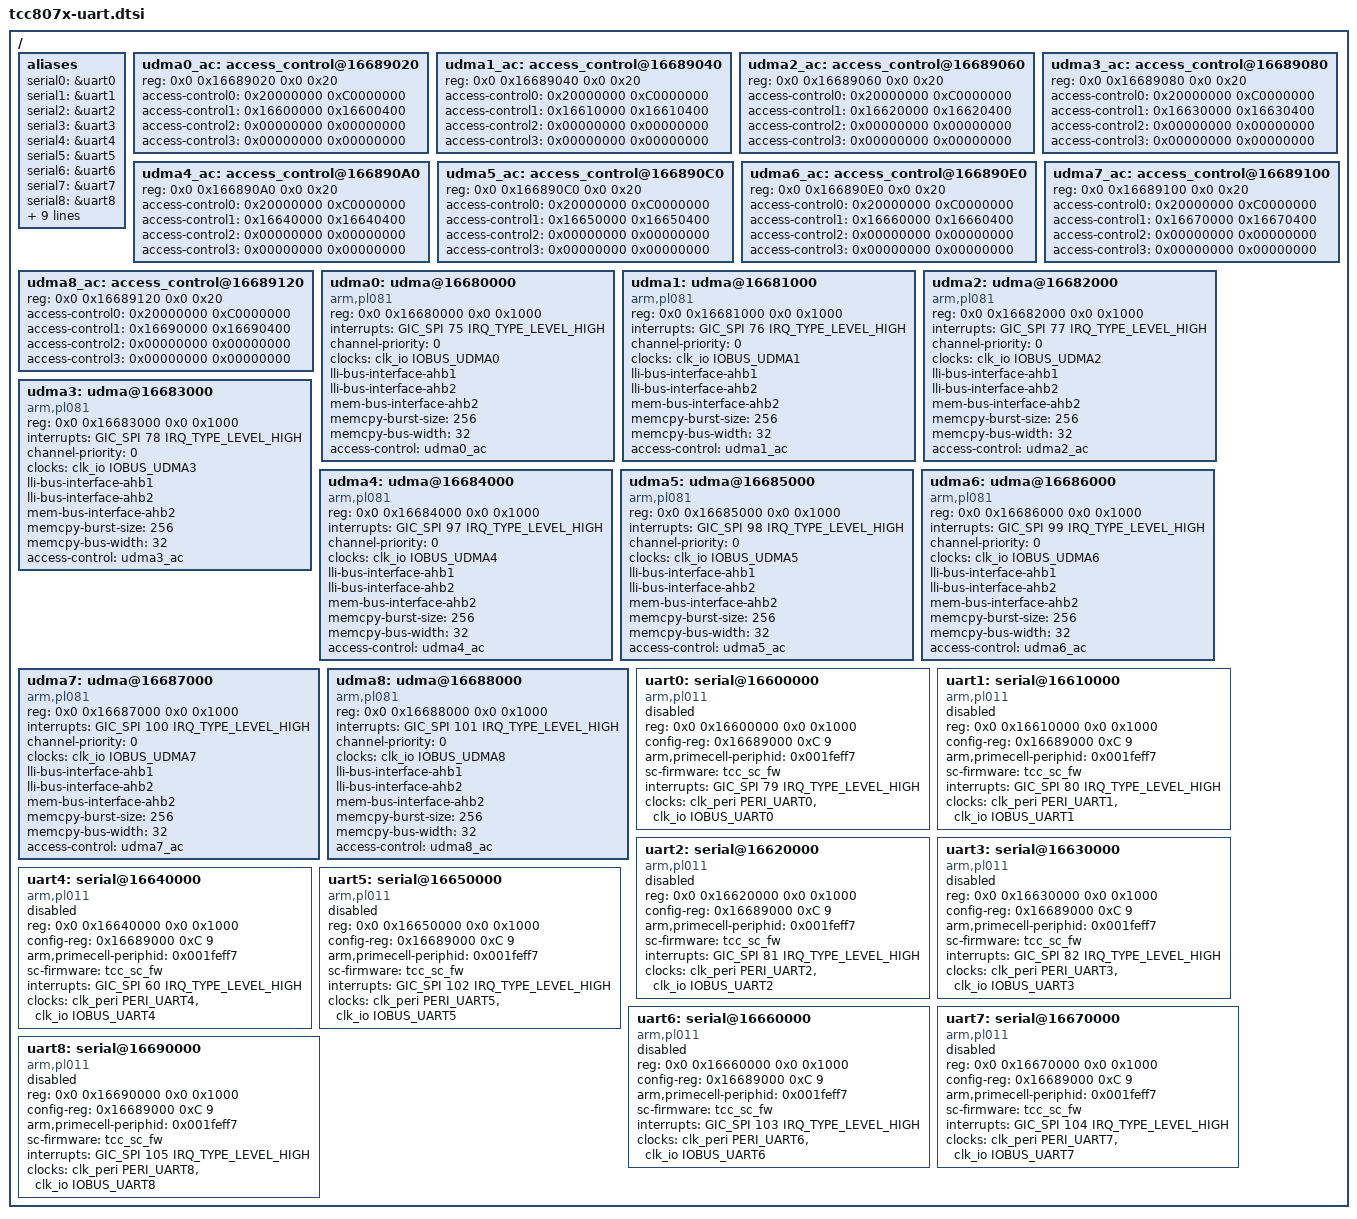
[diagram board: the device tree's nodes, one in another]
// SPDX-License-Identifier: (GPL-2.0-or-later OR MIT)
/*
 * Copyright (C) 2023 Telechips Inc.
 */

#include <dt-bindings/clock/telechips,tcc807x-clks.h>
#include <dt-bindings/interrupt-controller/arm-gic.h>

/ {
	aliases: aliases {
		serial0 = &uart0;
		serial1 = &uart1;
		serial2 = &uart2;
		serial3 = &uart3;
		serial4 = &uart4;
		serial5 = &uart5;
		serial6 = &uart6;
		serial7 = &uart7;
		serial8 = &uart8;
		udma0 = &udma0;
		udma1 = &udma1;
		udma2 = &udma2;
		udma3 = &udma3;
		udma4 = &udma4;
		udma5 = &udma5;
		udma6 = &udma6;
		udma7 = &udma7;
		udma8 = &udma8;
	};

	udma0_ac: access_control@16689020 {
		reg = <0x0 0x16689020 0x0 0x20>;
		access-control0 = <0x20000000 0xC0000000>; /* DRAM */
		access-control1 = <0x16600000 0x16600400>;
		access-control2 = <0x00000000 0x00000000>;
		access-control3 = <0x00000000 0x00000000>;
	};

	udma1_ac: access_control@16689040 {
		reg = <0x0 0x16689040 0x0 0x20>;
		access-control0 = <0x20000000 0xC0000000>; /* DRAM */
		access-control1 = <0x16610000 0x16610400>;
		access-control2 = <0x00000000 0x00000000>;
		access-control3 = <0x00000000 0x00000000>;
	};

	udma2_ac: access_control@16689060 {
		reg = <0x0 0x16689060 0x0 0x20>;
		access-control0 = <0x20000000 0xC0000000>; /* DRAM */
		access-control1 = <0x16620000 0x16620400>;
		access-control2 = <0x00000000 0x00000000>;
		access-control3 = <0x00000000 0x00000000>;
	};

	udma3_ac: access_control@16689080 {
		reg = <0x0 0x16689080 0x0 0x20>;
		access-control0 = <0x20000000 0xC0000000>; /* DRAM */
		access-control1 = <0x16630000 0x16630400>;
		access-control2 = <0x00000000 0x00000000>;
		access-control3 = <0x00000000 0x00000000>;
	};

	udma4_ac: access_control@166890A0 {
		reg = <0x0 0x166890A0 0x0 0x20>;
		access-control0 = <0x20000000 0xC0000000>; /* DRAM */
		access-control1 = <0x16640000 0x16640400>;
		access-control2 = <0x00000000 0x00000000>;
		access-control3 = <0x00000000 0x00000000>;
	};

	udma5_ac: access_control@166890C0 {
		reg = <0x0 0x166890C0 0x0 0x20>;
		access-control0 = <0x20000000 0xC0000000>; /* DRAM */
		access-control1 = <0x16650000 0x16650400>;
		access-control2 = <0x00000000 0x00000000>;
		access-control3 = <0x00000000 0x00000000>;
	};

	udma6_ac: access_control@166890E0 {
		reg = <0x0 0x166890E0 0x0 0x20>;
		access-control0 = <0x20000000 0xC0000000>; /* DRAM */
		access-control1 = <0x16660000 0x16660400>;
		access-control2 = <0x00000000 0x00000000>;
		access-control3 = <0x00000000 0x00000000>;
	};

	udma7_ac: access_control@16689100 {
		reg = <0x0 0x16689100 0x0 0x20>;
		access-control0 = <0x20000000 0xC0000000>; /* DRAM */
		access-control1 = <0x16670000 0x16670400>;
		access-control2 = <0x00000000 0x00000000>;
		access-control3 = <0x00000000 0x00000000>;
	};

	udma8_ac: access_control@16689120 {
		reg = <0x0 0x16689120 0x0 0x20>;
		access-control0 = <0x20000000 0xC0000000>; /* DRAM */
		access-control1 = <0x16690000 0x16690400>;
		access-control2 = <0x00000000 0x00000000>;
		access-control3 = <0x00000000 0x00000000>;
	};

	udma0: udma@16680000 {
		compatible = "arm,pl081", "arm,primecell";
		reg = <0x0 0x16680000 0x0 0x1000>;
		interrupts = <GIC_SPI 75 IRQ_TYPE_LEVEL_HIGH>;
		//dma-channels = <2>;
		//dma-requests = <32>;
		channel-priority = <0>;
		clocks = <&clk_io IOBUS_UDMA0>;
		clock-names = "apb_pclk";
		lli-bus-interface-ahb1;
		lli-bus-interface-ahb2;
		mem-bus-interface-ahb2;
		memcpy-burst-size = <256>;
		memcpy-bus-width = <32>;
		#dma-cells = <2>;
		access-control = <&udma0_ac>;
	};

	udma1: udma@16681000 {
		compatible = "arm,pl081", "arm,primecell";
		reg = <0x0 0x16681000 0x0 0x1000>;
		interrupts = <GIC_SPI 76 IRQ_TYPE_LEVEL_HIGH>;
		//dma-channels = <2>;
		//dma-requests = <32>;
		channel-priority = <0>;
		clocks = <&clk_io IOBUS_UDMA1>;
		clock-names = "apb_pclk";
		lli-bus-interface-ahb1;
		lli-bus-interface-ahb2;
		mem-bus-interface-ahb2;
		memcpy-burst-size = <256>;
		memcpy-bus-width = <32>;
		#dma-cells = <2>;
		access-control = <&udma1_ac>;
	};

	udma2: udma@16682000 {
		compatible = "arm,pl081", "arm,primecell";
		reg = <0x0 0x16682000 0x0 0x1000>;
		interrupts = <GIC_SPI 77 IRQ_TYPE_LEVEL_HIGH>;
		//dma-channels = <2>;
		//dma-requests = <32>;
		channel-priority = <0>;
		clocks = <&clk_io IOBUS_UDMA2>;
		clock-names = "apb_pclk";
		lli-bus-interface-ahb1;
		lli-bus-interface-ahb2;
		mem-bus-interface-ahb2;
		memcpy-burst-size = <256>;
		memcpy-bus-width = <32>;
		#dma-cells = <2>;
		access-control = <&udma2_ac>;
	};

	udma3: udma@16683000 {
		compatible = "arm,pl081", "arm,primecell";
		reg = <0x0 0x16683000 0x0 0x1000>;
		interrupts = <GIC_SPI 78 IRQ_TYPE_LEVEL_HIGH>;
		//dma-channels = <2>;
		//dma-requests = <32>;
		channel-priority = <0>;
		clocks = <&clk_io IOBUS_UDMA3>;
		clock-names = "apb_pclk";
		lli-bus-interface-ahb1;
		lli-bus-interface-ahb2;
		mem-bus-interface-ahb2;
		memcpy-burst-size = <256>;
		memcpy-bus-width = <32>;
		#dma-cells = <2>;
		access-control = <&udma3_ac>;
	};

	udma4: udma@16684000 {
		compatible = "arm,pl081", "arm,primecell";
		reg = <0x0 0x16684000 0x0 0x1000>;
		interrupts = <GIC_SPI 97 IRQ_TYPE_LEVEL_HIGH>;
		//dma-channels = <2>;
		//dma-requests = <32>;
		channel-priority = <0>;
		clocks = <&clk_io IOBUS_UDMA4>;
		clock-names = "apb_pclk";
		lli-bus-interface-ahb1;
		lli-bus-interface-ahb2;
		mem-bus-interface-ahb2;
		memcpy-burst-size = <256>;
		memcpy-bus-width = <32>;
		#dma-cells = <2>;
		access-control = <&udma4_ac>;
	};

	udma5: udma@16685000 {
		compatible = "arm,pl081", "arm,primecell";
		reg = <0x0 0x16685000 0x0 0x1000>;
		interrupts = <GIC_SPI 98 IRQ_TYPE_LEVEL_HIGH>;
		//dma-channels = <2>;
		//dma-requests = <32>;
		channel-priority = <0>;
		clocks = <&clk_io IOBUS_UDMA5>;
		clock-names = "apb_pclk";
		lli-bus-interface-ahb1;
		lli-bus-interface-ahb2;
		mem-bus-interface-ahb2;
		memcpy-burst-size = <256>;
		memcpy-bus-width = <32>;
		#dma-cells = <2>;
		access-control = <&udma5_ac>;
	};

	udma6: udma@16686000 {
		compatible = "arm,pl081", "arm,primecell";
		reg = <0x0 0x16686000 0x0 0x1000>;
		interrupts = <GIC_SPI 99 IRQ_TYPE_LEVEL_HIGH>;
		//dma-channels = <2>;
		//dma-requests = <32>;
		channel-priority = <0>;
		clocks = <&clk_io IOBUS_UDMA6>;
		clock-names = "apb_pclk";
		lli-bus-interface-ahb1;
		lli-bus-interface-ahb2;
		mem-bus-interface-ahb2;
		memcpy-burst-size = <256>;
		memcpy-bus-width = <32>;
		#dma-cells = <2>;
		access-control = <&udma6_ac>;
	};

	udma7: udma@16687000 {
		compatible = "arm,pl081", "arm,primecell";
		reg = <0x0 0x16687000 0x0 0x1000>;
		interrupts = <GIC_SPI 100 IRQ_TYPE_LEVEL_HIGH>;
		//dma-channels = <2>;
		//dma-requests = <32>;
		channel-priority = <0>;
		clocks = <&clk_io IOBUS_UDMA7>;
		clock-names = "apb_pclk";
		lli-bus-interface-ahb1;
		lli-bus-interface-ahb2;
		mem-bus-interface-ahb2;
		memcpy-burst-size = <256>;
		memcpy-bus-width = <32>;
		#dma-cells = <2>;
		access-control = <&udma7_ac>;
	};

	udma8: udma@16688000 {
		compatible = "arm,pl081", "arm,primecell";
		reg = <0x0 0x16688000 0x0 0x1000>;
		interrupts = <GIC_SPI 101 IRQ_TYPE_LEVEL_HIGH>;
		//dma-channels = <2>;
		//dma-requests = <32>;
		channel-priority = <0>;
		clocks = <&clk_io IOBUS_UDMA8>;
		clock-names = "apb_pclk";
		lli-bus-interface-ahb1;
		lli-bus-interface-ahb2;
		mem-bus-interface-ahb2;
		memcpy-burst-size = <256>;
		memcpy-bus-width = <32>;
		#dma-cells = <2>;
		access-control = <&udma8_ac>;
	};

	uart0: serial@16600000 {
		compatible = "arm,pl011", "arm,primecell";
		reg = <0x0 0x16600000 0x0 0x1000>;
		config-reg = <0x16689000 0xC 9>;
		arm,primecell-periphid = <0x001feff7>;
		sc-firmware = <&tcc_sc_fw>;
		interrupts = <GIC_SPI 79 IRQ_TYPE_LEVEL_HIGH>;
		clocks = <&clk_peri PERI_UART0>, <&clk_io IOBUS_UART0>;
		clock-names = "uartclk", "apb_pclk";
		status = "disabled";
	};

	uart1: serial@16610000 {
		compatible = "arm,pl011", "arm,primecell";
		reg = <0x0 0x16610000 0x0 0x1000>;
		config-reg = <0x16689000 0xC 9>;
		arm,primecell-periphid = <0x001feff7>;
		sc-firmware = <&tcc_sc_fw>;
		interrupts = <GIC_SPI 80 IRQ_TYPE_LEVEL_HIGH>;
		clocks = <&clk_peri PERI_UART1>, <&clk_io IOBUS_UART1>;
		clock-names = "uartclk", "apb_pclk";
		status = "disabled";
	};

	uart2: serial@16620000 {
		compatible = "arm,pl011", "arm,primecell";
		reg = <0x0 0x16620000 0x0 0x1000>;
		config-reg = <0x16689000 0xC 9>;
		arm,primecell-periphid = <0x001feff7>;
		sc-firmware = <&tcc_sc_fw>;
		interrupts = <GIC_SPI 81 IRQ_TYPE_LEVEL_HIGH>;
		clocks = <&clk_peri PERI_UART2>, <&clk_io IOBUS_UART2>;
		clock-names = "uartclk", "apb_pclk";
		status = "disabled";
	};

	uart3: serial@16630000 {
		compatible = "arm,pl011", "arm,primecell";
		reg = <0x0 0x16630000 0x0 0x1000>;
		config-reg = <0x16689000 0xC 9>;
		arm,primecell-periphid = <0x001feff7>;
		sc-firmware = <&tcc_sc_fw>;
		interrupts = <GIC_SPI 82 IRQ_TYPE_LEVEL_HIGH>;
		clocks = <&clk_peri PERI_UART3>, <&clk_io IOBUS_UART3>;
		clock-names = "uartclk", "apb_pclk";
		status = "disabled";
	};

	uart4: serial@16640000 {
		compatible = "arm,pl011", "arm,primecell";
		reg = <0x0 0x16640000 0x0 0x1000>;
		config-reg = <0x16689000 0xC 9>;
		arm,primecell-periphid = <0x001feff7>;
		sc-firmware = <&tcc_sc_fw>;
		interrupts = <GIC_SPI 60 IRQ_TYPE_LEVEL_HIGH>;
		clocks = <&clk_peri PERI_UART4>, <&clk_io IOBUS_UART4>;
		clock-names = "uartclk", "apb_pclk";
		status = "disabled";
	};

	uart5: serial@16650000 {
		compatible = "arm,pl011", "arm,primecell";
		reg = <0x0 0x16650000 0x0 0x1000>;
		config-reg = <0x16689000 0xC 9>;
		arm,primecell-periphid = <0x001feff7>;
		sc-firmware = <&tcc_sc_fw>;
		interrupts = <GIC_SPI 102 IRQ_TYPE_LEVEL_HIGH>;
		clocks = <&clk_peri PERI_UART5>, <&clk_io IOBUS_UART5>;
		clock-names = "uartclk", "apb_pclk";
		status = "disabled";
	};

	uart6: serial@16660000 {
		compatible = "arm,pl011", "arm,primecell";
		reg = <0x0 0x16660000 0x0 0x1000>;
		config-reg = <0x16689000 0xC 9>;
		arm,primecell-periphid = <0x001feff7>;
		sc-firmware = <&tcc_sc_fw>;
		interrupts = <GIC_SPI 103 IRQ_TYPE_LEVEL_HIGH>;
		clocks = <&clk_peri PERI_UART6>, <&clk_io IOBUS_UART6>;
		clock-names = "uartclk", "apb_pclk";
		status = "disabled";
	};

	uart7: serial@16670000 {
		compatible = "arm,pl011", "arm,primecell";
		reg = <0x0 0x16670000 0x0 0x1000>;
		config-reg = <0x16689000 0xC 9>;
		arm,primecell-periphid = <0x001feff7>;
		sc-firmware = <&tcc_sc_fw>;
		interrupts = <GIC_SPI 104 IRQ_TYPE_LEVEL_HIGH>;
		clocks = <&clk_peri PERI_UART7>, <&clk_io IOBUS_UART7>;
		clock-names = "uartclk", "apb_pclk";
		status = "disabled";
	};

	uart8: serial@16690000 {
		compatible = "arm,pl011", "arm,primecell";
		reg = <0x0 0x16690000 0x0 0x1000>;
		config-reg = <0x16689000 0xC 9>;
		arm,primecell-periphid = <0x001feff7>;
		sc-firmware = <&tcc_sc_fw>;
		interrupts = <GIC_SPI 105 IRQ_TYPE_LEVEL_HIGH>;
		clocks = <&clk_peri PERI_UART8>, <&clk_io IOBUS_UART8>;
		clock-names = "uartclk", "apb_pclk";
		status = "disabled";
	};
};
